# M3351 register map
File version: 1.0
Registers are 32-bit, read-write, reset 0x0 unless marked. A register's access mark holds for its fields unless they carry their own. Offsets are from the block's base; [hi:lo] are bit positions; {n}, {i} and the like mark numbered series; 'fields as' and 'values as' point back to an identical list.

## SYS — SYS Register Map
Base 0x40000000
0x00 SYS_PDID ro reset 0x3302140 — Part Device Identification Number Register
  [31:0] PDID — Part Device Identification Number (Read Only). This register reflects device part number code. Software can read this register to identify which device is used.
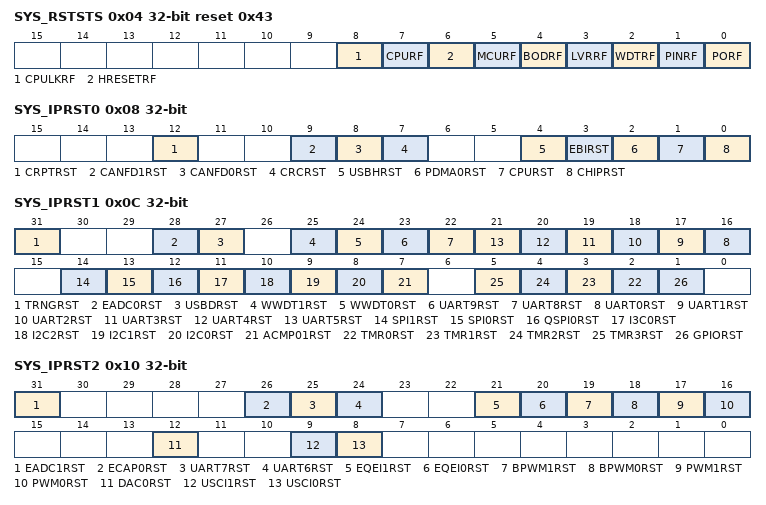
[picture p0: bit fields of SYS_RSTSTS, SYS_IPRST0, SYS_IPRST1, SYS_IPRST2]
0x04 SYS_RSTSTS reset 0x43 — System Reset Status Register
  [8] CPULKRF — CPU Lockup Reset Flag. Note 1: Write 1 to clear this bit to 0. Note 2: When CPU lockup happened under ICE is connected, this flag will set to 1 but chip will not reset.
    0=No reset from CPU lockup happened; 1=The Cortex-M33 lockup happened and chip is reset
  [7] CPURF — CPU Reset Flag. The CPU reset flag is set by hardware if software writes CPURST (SYS_IPRST0[1]) 1 to reset Cortex-M33 Core and Flash Memory Controller (FMC). Note: Write 1 to clear this bit to 0.
    0=No reset from CPU; 1=The Cortex-M33 Core and FMC are reset by software setting CPURST to 1
  [6] HRESETRF — HRESET Reset Flag. The HRESET reset flag is set by the 'Reset Signal' from the HRESET. Note 1: Write 1 to clear this bit to 0. Note 2: HRESET includes: POR, Reset Pin, LVR, BOD, WDT, WWDT, CPU lockup, CHIP and MCU reset.
    0=No reset from HRESET; 1=Reset from HRESET
  [5] MCURF — MCU Reset Flag. The MCU reset flag is set by the 'Reset Signal' from the Cortex-M33 Core to indicate the previous reset source. Note: Write 1 to clear this bit to 0.
    0=No reset from Cortex-M33; 1=The Cortex-M33 had issued the reset signal to reset the system by writing 1 to the bit SYSRESETREQ(AIRCR[2], Application Interrupt and Reset Control Register, address = 0xE000ED0C) in system control registers of Cortex-M33 core
  [4] BODRF — BOD Reset Flag. The BOD reset flag is set by the 'Reset Signal' from the Brown-Out Detector to indicate the previous reset source. Note: Write 1 to clear this bit to 0.
    0=No reset from BOD; 1=The BOD had issued the reset signal to reset the system
  [3] LVRRF — LVR Reset Flag. The LVR reset flag is set by the 'Reset Signal' from the Low Voltage Reset Controller to indicate the previous reset source. Note: Write 1 to clear this bit to 0.
    0=No reset from LVR; 1=LVR controller had issued the reset signal to reset the system
  [2] WDTRF — WDT Reset Flag. The WDT reset flag is set by the 'Reset Signal' from the Watchdog Timer or Window Watchdog Timer to indicate the previous reset source. Note 1: Write 1 to clear this bit to 0. Note 2: Watchdog Timer register RSTF(WDT_CTL[2]) bit is set if the system has been reset by WDT time-out reset. Window Watchdog Timer register WWDTRF(WWDT_STATUS[1]) bit is set if the system has been reset by WWDT time-out reset.
    0=No reset from watchdog timer or window watchdog timer; 1=The watchdog timer or window watchdog timer had issued the reset signal to reset the system
  [1] PINRF — NRESET Pin Reset Flag. The nRESET pin reset flag is set by the 'Reset Signal' from the nRESET pin to indicate the previous reset source. Note: Write 1 to clear this bit to 0.
    0=No reset from nRESET pin; 1=Pin nRESET had issued the reset signal to reset the system
  [0] PORF — POR Reset Flag. The POR reset flag is set by the 'Reset Signal' from the Power-on Reset (POR) Controller or bit CHIPRST (SYS_IPRST0[0]) to indicate the previous reset source. Note: Write 1 to clear this bit to 0.
    0=No reset from POR or CHIPRST; 1=Power-on Reset (POR) or CHIPRST had issued the reset signal to reset the system
0x08 SYS_IPRST0 — Peripheral Reset Control Register 0
  [12] CRPTRST — CRYPTO Controller Reset (Write Protect). Setting this bit to 1 will generate a reset signal to the CRYPTO controller. User needs to set this bit to 0 to release from the reset state. Note: This bit is write protected. Refer to the SYS_REGLCTL register.
    0=CRYPTO controller normal operation; 1=CRYPTO controller reset
  [9] CANFD1RST — CANFD1 Controller Reset (Write Protect). Setting this bit to 1 will generate a reset signal to the CANFD1 controller. User needs to set this bit to 0 to release from reset state. Note: This bit is write protected. Refer to the SYS_REGLCTL register.
    0=CANFD1 controller normal operation; 1=CANFD1 controller reset
  [8] CANFD0RST — CANFD0 Controller Reset (Write Protect). Setting this bit to 1 will generate a reset signal to the CANFD0 controller. User needs to set this bit to 0 to release from reset state. Note: This bit is write protected. Refer to the SYS_REGLCTL register.
    0=CANFD0 controller normal operation; 1=CANFD0 controller reset
  [7] CRCRST — CRC Calculation Controller Reset (Write Protect). Set this bit to 1 will generate a reset signal to the CRC calculation controller. User needs to set this bit to 0 to release from the reset state. Note: This bit is write protected. Refer to the SYS_REGLCTL register.
    0=CRC calculation controller normal operation; 1=CRC calculation controller reset
  [4] USBHRST — USBH Controller Reset (Write Protect). Setting this bit to 1 will generate a reset signal to the USBH controller. User needs to set this bit to 0 to release from the reset state. Note: This bit is write protected. Refer to the SYS_REGLCTL register.
    0=USBH controller normal operation; 1=USBH controller reset
  [3] EBIRST — EBI Controller Reset (Write Protect). Set this bit to 1 will generate a reset signal to the EBI controller. User needs to set this bit to 0 to release from the reset state. Note: This bit is write protected. Refer to the SYS_REGLCTL register.
    0=EBI controller normal operation; 1=EBI controller reset
  [2] PDMA0RST — PDMA0 Controller Reset (Write Protect). Setting this bit to 1 will generate a reset signal to the PDMA0 controller. User needs to set this bit to 0 to release from reset state. Note: This bit is write protected. Refer to the SYS_REGLCTL register.
    0=PDMA0 controller normal operation; 1=PDMA0 controller reset
  [1] CPURST — Processor Core One-shot Reset (Write Protect). Setting this bit will only reset the processor core and Flash Memory Controller(FMC), and this bit will automatically return to 0 after the 2 clock cycles. Note: This bit is write protected. Refer to the SYS_REGLCTL register.
    0=Processor core normal operation; 1=Processor core one-shot reset
  [0] CHIPRST — Chip One-shot Reset (Write Protect). Setting this bit will reset the whole chip, including Processor core and all peripherals, and this bit will automatically return to 0 after the 2 clock cycles. The CHIPRST is same as the POR reset, all the chip controllers are reset and the chip setting from Flash are also reload. About the difference between CHIPRST and SYSRESETREQ(AIRCR[2]), please refer to System Reset section. Note: This bit is write protected. Refer to the SYS_REGLCTL register.
    0=Chip normal operation; 1=Chip one-shot reset
0x0C SYS_IPRST1 — Peripheral Reset Control Register 1
  [31] TRNGRST — TRNG Controller Reset. Setting this bit to 1 will generate a reset signal to the TRNG controller. User needs to set this bit to 0 to release from reset state.
    0=TRNG controller normal operation; 1=TRNG controller reset
  [28] EADC0RST — EADC0 Controller Reset. Setting this bit to 1 will generate a reset signal to the EADC0 controller. User needs to set this bit to 0 to release from reset state.
    0=EADC0 controller normal operation; 1=EADC0 controller reset
  [27] USBDRST — USBD Controller Reset. Setting this bit to 1 will generate a reset signal to the USBD controller. User needs to set this bit to 0 to release from reset state.
    0=USBD controller normal operation; 1=USBD controller reset
  [25] WWDT1RST — WWDT1 Controller Reset. Setting this bit to 1 will generate a reset signal to the WWDT1 controller. User needs to set this bit to 0 to release from reset state.
    0=WWDT1 controller normal operation; 1=WWDT1 controller reset
  [24] WWDT0RST — WWDT0 Controller Reset. Setting this bit to 1 will generate a reset signal to the WWDT0 controller. User needs to set this bit to 0 to release from reset state.
    0=WWDT0 controller normal operation; 1=WWDT0 controller reset
  [23] UART9RST — UART9 Controller Reset. Setting this bit to 1 will generate a reset signal to the UART9 controller. User needs to set this bit to 0 to release from reset state.
    0=UART9 controller normal operation; 1=UART9 controller reset
  [22] UART8RST — UART8 Controller Reset. Setting this bit to 1 will generate a reset signal to the UART8 controller. User needs to set this bit to 0 to release from reset state.
    0=UART8 controller normal operation; 1=UART8 controller reset
  [n+16] UART{n}RST (n=0..5) — UART{n} Controller Reset. Setting this bit to 1 will generate a reset signal to the UART{n} controller. User needs to set this bit to 0 to release from reset state.
    0=UART{n} controller normal operation; 1=UART{n} controller reset
  [14] SPI1RST — SPI1 Controller Reset. Setting this bit to 1 will generate a reset signal to the SPI1 controller. User needs to set this bit to 0 to release from reset state.
    0=SPI1 controller normal operation; 1=SPI1 controller reset
  [13] SPI0RST — SPI0 Controller Reset. Setting this bit to 1 will generate a reset signal to the SPI0 controller. User needs to set this bit to 0 to release from reset state.
    0=SPI0 controller normal operation; 1=SPI0 controller reset
  [12] QSPI0RST — QSPI0 Controller Reset. Setting this bit to 1 will generate a reset signal to the QSPI0 controller. User needs to set this bit to 0 to release from reset state.
    0=QSPI0 controller normal operation; 1=QSPI0 controller reset
  [11] I3C0RST — I3C0 Controller Reset. Setting this bit to 1 will generate a reset signal to the I3C0 controller. User needs to set this bit to 0 to release from reset state.
    0=I3C0 normal operation; 1=I3C0 reset
  [10] I2C2RST — I2C2 Controller Reset. Setting this bit to 1 will generate a reset signal to the I2C2 controller. User needs to set this bit to 0 to release from reset state.
    0=I2C2 controller normal operation; 1=I2C2 controller reset
  [9] I2C1RST — I2C1 Controller Reset. Setting this bit to 1 will generate a reset signal to the I2C1 controller. User needs to set this bit to 0 to release from reset state.
    0=I2C1 controller normal operation; 1=I2C1 controller reset
  [8] I2C0RST — I2C0 Controller Reset. Setting this bit to 1 will generate a reset signal to the I2C0 controller. User needs to set this bit to 0 to release from reset state.
    0=I2C0 controller normal operation; 1=I2C0 controller reset
  [7] ACMP01RST — Analog Comparator 0/1 Controller Reset. Setting this bit to 1 will generate a reset signal to the ACMP01 controller. User needs to set this bit to 0 to release from reset state.
    0=Analog Comparator 0/1 controller normal operation; 1=Analog Comparator 0/1 controller reset
  [n+2] TMR{n}RST (n=0..3) — Timer{n} Controller Reset. Setting this bit to 1 will generate a reset signal to the Timer{n} controller. User needs to set this bit to 0 to release from reset state.
    0=Timer{n} controller normal operation; 1=Timer{n} controller reset
  [1] GPIORST — GPIO Controller Reset. Setting this bit to 1 will generate a reset signal to the GPIO controller. User needs to set this bit to 0 to release from reset state.
    0=GPIO controller normal operation; 1=GPIO controller reset
0x10 SYS_IPRST2 — Peripheral Reset Control Register 2
  [31] EADC1RST — EADC1 Controller Reset. Setting this bit to 1 will generate a reset signal to the EADC1 controller. User needs to set this bit to 0 to release from reset state.
    0=EADC1 controller normal operation; 1=EADC1 controller reset
  [26] ECAP0RST — ECAP0 Controller Reset. Setting this bit to 1 will generate a reset signal to the ECAP0 controller. User needs to set this bit to 0 to release from reset state.
    0=ECAP0 controller normal operation; 1=ECAP0 controller reset
  [25] UART7RST — UART7 Controller Reset. Setting this bit to 1 will generate a reset signal to the UART7 controller. User needs to set this bit to 0 to release from reset state.
    0=UART7 controller normal operation; 1=UART7 controller reset
  [24] UART6RST — UART6 Controller Reset. Setting this bit to 1 will generate a reset signal to the UART6 controller. User needs to set this bit to 0 to release from reset state.
    0=UART6 controller normal operation; 1=UART6 controller reset
  [21] EQEI1RST — EQEI1 Controller Reset. Setting this bit to 1 will generate a reset signal to the EQEI1 controller. User needs to set this bit to 0 to release from reset state.
    0=EQEI1 controller normal operation; 1=EQEI1 controller reset
  [20] EQEI0RST — EQEI0 Controller Reset. Setting this bit to 1 will generate a reset signal to the EQEI0 controller. User needs to set this bit to 0 to release from reset state.
    0=EQEI0 controller normal operation; 1=EQEI0 controller reset
  [19] BPWM1RST — BPWM1 Controller Reset. Setting this bit to 1 will generate a reset signal to the BPWM1 controller. User needs to set this bit to 0 to release from reset state.
    0=BPWM1 controller normal operation; 1=BPWM1 controller reset
  [18] BPWM0RST — BPWM0 Controller Reset. Setting this bit to 1 will generate a reset signal to the BPWM0 controller. User needs to set this bit to 0 to release from reset state.
    0=BPWM0 controller normal operation; 1=BPWM0 controller reset
  [17] PWM1RST — PWM1 Controller Reset. Setting this bit to 1 will generate a reset signal to the PWM1 controller. User needs to set this bit to 0 to release from reset state.
    0=PWM1 controller normal operation; 1=PWM1 controller reset
  [16] PWM0RST — PWM0 Controller Reset. Setting this bit to 1 will generate a reset signal to the PWM0 controller. User needs to set this bit to 0 to release from reset state.
    0=PWM0 controller normal operation; 1=PWM0 controller reset
  [12] DAC0RST — DAC0 Controller Reset. Setting this bit to 1 will generate a reset signal to the DAC0 controller. User needs to set this bit to 0 to release from reset state.
    0=DAC0 controller normal operation; 1=DAC0 controller reset
  [9] USCI1RST — USCI1 Controller Reset. Setting this bit to 1 will generate a reset signal to the USCI1 controller. User needs to set this bit to 0 to release from reset state.
    0=USCI1 controller normal operation; 1=USCI1 controller reset
  [8] USCI0RST — USCI0 Controller Reset. Setting this bit to 1 will generate a reset signal to the USCI0 controller. User needs to set this bit to 0 to release from reset state.
    0=USCI0 controller normal operation; 1=USCI0 controller reset
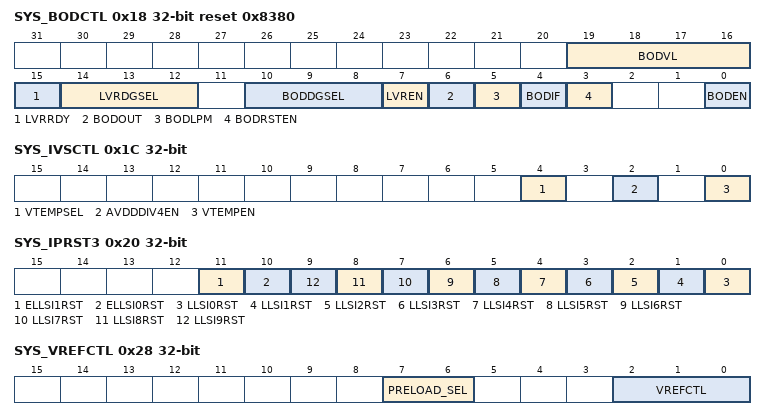
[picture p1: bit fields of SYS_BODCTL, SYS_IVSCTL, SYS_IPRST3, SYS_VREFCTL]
0x18 SYS_BODCTL reset 0x8380 (reset mask 0xFFF0FFF0) — Brown-out Detector Control Register
  [19:16] BODVL — Brown-out Detector Threshold Voltage Selection (Write Protect). The default value is set by Flash controller user configuration register CBOV ({1'b1, CONFIG0 [23:21]}). Note: These bits are write protected. Refer to the SYS_REGLCTL register.
    11=Brown-Out Detector threshold voltage is 2.8V; 13=Brown-Out Detector threshold voltage is 3.7V; 15=Brown-Out Detector threshold voltage is 4.4V
  [15] LVRRDY — Low Voltage Reset Ready Flag (Read Only). When the LVR function first enable, need more HCLK to wait LVR ready.
    0=Low Voltage Reset function not ready; 1=Low Voltage Reset function ready
  [14:12] LVRDGSEL — LVR Output De-glitch Time Select (Write Protect). Note: These bits are write protected. Refer to the SYS_REGLCTL register.
    0=Without de-glitch function; 1=4 system clock (HCLK); 2=8 system clock (HCLK); 3=16 system clock (HCLK); 4=32 system clock (HCLK); 5=64 system clock (HCLK); 6=128 system clock (HCLK); 7=256 system clock (HCLK)
  [10:8] BODDGSEL — Brown-out Detector Output De-glitch Time Select (Write Protect). Note: These bits are write protected. Refer to the SYS_REGLCTL register.
    0=BOD output is sampled by LIRC clock; 1=4 system clock (HCLK); 2=8 system clock (HCLK); 3=16 system clock (HCLK); 4=32 system clock (HCLK); 5=64 system clock (HCLK); 6=128 system clock (HCLK); 7=256 system clock (HCLK)
  [7] LVREN — Low Voltage Reset Enable Bit (Write Protect). The LVR function resets the chip when the input power voltage is lower than LVR circuit setting. Note 1: After enabling the bit, the LVR function will be active with 100us ~ 200us delay for LVR output stable. LVRRDY(SYS_BODCTL[15]) is used to indicate LVR ready status. Note 2: This bit is write protected. Refer to the SYS_REGLCTL register.
    0=Low Voltage Reset function Disabled; 1=Low Voltage Reset function Enabled (default)
  [6] BODOUT — Brown-out Detector Output Status. It means the detected voltage is lower than BODVL setting. If the BODEN is 0, BOD function disabled, this bit always responds 0.
    0=Brown-out Detector output status is 0; 1=Brown-out Detector output status is 1
  [5] BODLPM — Brown-out Detector Low Power Mode (Write Protect). Note 1: The BOD consumes about 100uA in normal mode, the low power mode can reduce the current to about 1/10 but slow the BOD response. Note 2: This bit is write protected. Refer to the SYS_REGLCTL register.
    0=BOD operate in normal mode (default); 1=BOD Low Power mode Enabled
  [4] BODIF — Brown-out Detector Interrupt Flag. Note: Write 1 to clear this bit to 0.
    0=Brown-out Detector does not detect any voltage draft at AVDD down through or up through the voltage of BODVL setting; 1=When Brown-out Detector detects the AVDD is dropped down through the voltage of BODVL setting or the AVDD is raised up through the voltage of BODVL setting, this bit is set to 1 and the brown-out interrupt is requested if brown-out interrupt is enabled
  [3] BODRSTEN — Brown-out Reset Enable Bit (Write Protect). The default value is set by Flash controller user configuration register CBORST(CONFIG0[20]) bit. Note 1: While the Brown-out Detector function is enabled (BODEN high) and BOD reset function is enabled (BODRSTEN high), BOD will assert a signal to reset chip when the detected voltage is lower than the threshold (BODOUT high). While the BOD function is enabled (BODEN high) and BOD interrupt function is enabled (BODRSTEN low), BOD will assert an interrupt if BODIF is high. BOD interrupt will keep till the BODIF set to 0. BOD interrupt can be blocked by disabling the NVIC BOD interrupt or disabling BOD function (set BODEN low). Note 2: This bit is write protected. Refer to the SYS_REGLCTL register.
    0=Brown-out 'INTERRUPT' function Enabled; 1=Brown-out 'RESET' function Enabled
  [0] BODEN — Brown-out Detector Enable Bit (Write Protect). The default value is set by Flash controller user configuration register CBODEN (CONFIG0 [19]). Note: This bit is write protected. Refer to the SYS_REGLCTL register.
    0=Brown-out Detector function Disabled; 1=Brown-out Detector function Enabled
0x1C SYS_IVSCTL — Internal Voltage Source Control Register
  [4] VTEMPSEL — Temperature Sensor Slope Select Bit. This bit is used to select temperature sensor slope trend.
    0=Temperature sensor CTAT slope; 1=Temperature sensor PTAT slope
  [2] AVDDDIV4EN — AVDD Divide 4 Enable Bit. This bit is used to enable/disable AVDD divide 4 function. Note: After this bit is set to 1, the value of AVDD divide 4 output voltage can be obtained from ADC conversion result.
    0=AVDD divide 4 function Disabled (default); 1=AVDD divide 4 function Enabled
  [0] VTEMPEN — Temperature Sensor Enable Bit. This bit is used to enable/disable temperature sensor function.
    0=Temperature sensor function Disabled (default); 1=Temperature sensor function Enabled
0x20 SYS_IPRST3 — Peripheral Reset Control Register 3
  [11] ELLSI1RST — ELLSI1 Controller Reset
    0=ELLSI1 normal operation; 1=ELLSI1 reset
  [10] ELLSI0RST — ELLSI0 Controller Reset
    0=ELLSI0 normal operation; 1=ELLSI0 reset
  [n] LLSI{n}RST (n=0..9) — LLSI{n} Controller Reset
    0=LLSI{n} normal operation; 1=LLSI{n} reset
0x28 SYS_VREFCTL — VREF Control Register
  [7:6] PRELOAD_SEL — VREF Preload Time Select (Write Protect). Note: These bits are write protected. Refer to the SYS_REGLCTL register.
    0=60us (default); 1=966us; 2=2000us; 3=2.65ms
  [2:0] VREFCTL — VREF Control Bits (Write Protect). Note: These bits are write protected. Refer to the SYS_REGLCTL register.
    0=VREF is from external pin; 3=VREF is internal 2.56V; 5=VREF is internal 3.072V; 7=VREF is internal 4.096V
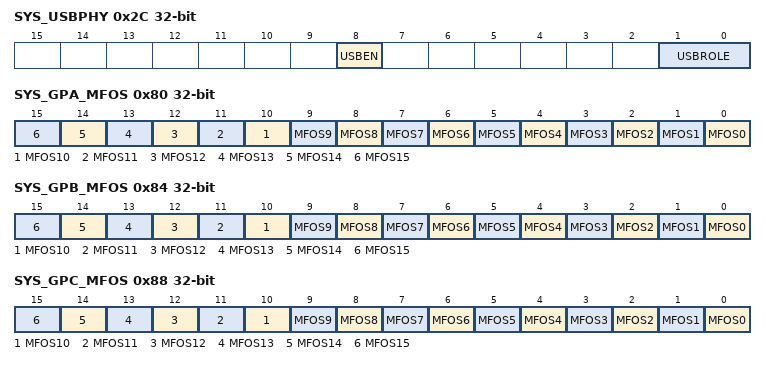
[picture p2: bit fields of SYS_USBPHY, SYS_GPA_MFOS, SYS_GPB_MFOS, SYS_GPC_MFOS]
0x2C SYS_USBPHY — USB PHY Control Register
  [8] USBEN — USB PHY Enable. This bit is used to enable/disable USB PHY.
    0=USB PHY Disabled; 1=USB PHY Enabled
  [1:0] USBROLE — USB Role Option (Write Protect). These two bits are used to select the role of USB. Note: These bits are write protected. Refer to the SYS_REGLCTL register.
    0=Standard USB Device mode; 1=Standard USB Host mode
0x80 SYS_GPA_MFOS — GPIOA Multiple Function Output Select Register
  [all] fields
    0=Multiple function pin output mode type is Push-pull mode; 1=Multiple function pin output mode type is Open-drain mode
  [n] MFOS{n} (n=0..15) — GPIOA-H Pin[n] Multiple Function Pin Output Mode Select. This bit used to select multiple function pin output mode type for Px.n pin.
0x84 SYS_GPB_MFOS — GPIOB Multiple Function Output Select Register
  fields as SYS_GPA_MFOS
0x88 SYS_GPC_MFOS — GPIOC Multiple Function Output Select Register
  fields as SYS_GPA_MFOS
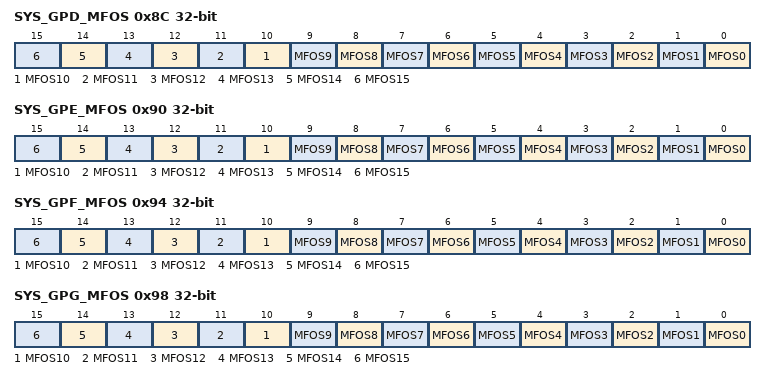
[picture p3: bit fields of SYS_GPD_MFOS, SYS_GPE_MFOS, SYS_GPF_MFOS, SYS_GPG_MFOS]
0x8C SYS_GPD_MFOS — GPIOD Multiple Function Output Select Register
  fields as SYS_GPA_MFOS
0x90 SYS_GPE_MFOS — GPIOE Multiple Function Output Select Register
  fields as SYS_GPA_MFOS
0x94 SYS_GPF_MFOS — GPIOF Multiple Function Output Select Register
  fields as SYS_GPA_MFOS
0x98 SYS_GPG_MFOS — GPIOG Multiple Function Output Select Register
  fields as SYS_GPA_MFOS
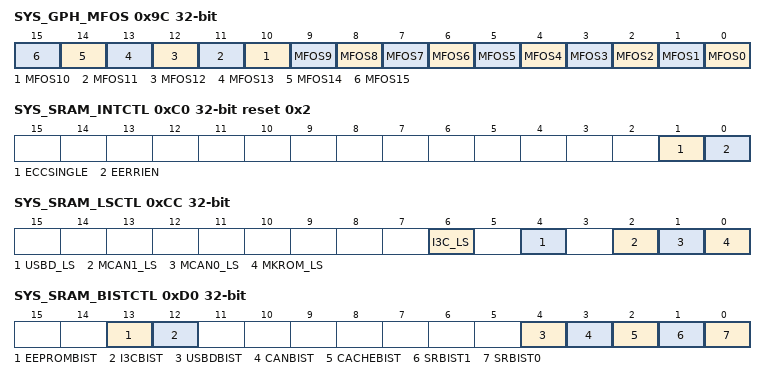
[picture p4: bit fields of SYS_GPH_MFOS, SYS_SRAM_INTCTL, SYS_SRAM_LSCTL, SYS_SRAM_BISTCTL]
0x9C SYS_GPH_MFOS — GPIOH Multiple Function Output Select Register
  fields as SYS_GPA_MFOS
0xA8 SYS_VTORSET — VTOR Setting Register
  [31:7] VTORSET — VTOR Setting After SPD Wakeup (Write Protect). This is the register to set the address of vector table after chip is waked up from SPD mode. The value will be loaded to Vector Table Offset Register, which is at the address 0xE000ED08, when chip wake up from SPD mode. Note: These bits are write protected. Refer to the SYS_REGLCTL register.
0xC0 SYS_SRAM_INTCTL reset 0x2 — System SRAM Secure ECC Interrupt Enable Control Register
  [1] ECCSINGLE — SRAM ECC Check single Error Enable Bit
    0=SRAM ECC check single error Disabled; 1=SRAM ECC check single error Enabled
  [0] EERRIEN — SRAM ECC Check Error Interrupt Enable Bit
    0=SRAM ECC check error interrupt Disabled; 1=SRAM ECC check error interrupt Enabled
0xC4 SYS_SRAM_STATUS — System SRAM Secure ECC Status Register
  [0] EERRIF — SRAM ECC Check Error Flag. This bit indicates the System SRAM ECC error occurred. Write 1 to clear this to 0. *This function only works if ECCEN set to 1.
    0=No System SRAM ECC error; 1=System SRAM ECC error occur
0xC8 SYS_SRAM_ERRADDR ro — System SRAM Secure ECC Error Address Register
  [31:0] ERRADDR — System SRAM ECC Error Address (Read Only). This register shows system SRAM ECC error byte address.(If ECC errors are detected in multiple SRAM banks, a single address will be randomly chosen for reporting). Note: This function only works if ECCEN set to 1.
0xCC SYS_SRAM_LSCTL — SRAM Light Sleep Control Register
  [all] fields
    0=Light Sleep disable; 1=Light Sleep enable, SRAM goes into low leakage mode, there is no change in the output state
  [6] I3C_LS — I3C SRAM Light Sleep Mode Enable bit (Write Protect). Note: This bit is write protected. Refer to the SYS_REGLCTL register.
  [4] USBD_LS — USBD SRAM Light Sleep Mode Enable bit (Write Protect). Note: This bit is write protected. Refer to the SYS_REGLCTL register.
  [2] MCAN1_LS — MCAN1 SRAM Light Sleep Mode Enable bit (Write Protect). Note: This bit is write protected. Refer to the SYS_REGLCTL register.
  [1] MCAN0_LS — MCAN0 SRAM Light Sleep Mode Enable bit (Write Protect). Note: This bit is write protected. Refer to the SYS_REGLCTL register.
  [0] MKROM_LS — MKROM Light Sleep Mode Enable bit (Write Protect). Note: This bit is write protected. Refer to the SYS_REGLCTL register.
0xD0 SYS_SRAM_BISTCTL — System SRAM BIST Test Control Register
  [13] EEPROMBIST — EEPROM SRAM BIST Enable Bit (Write Protect). This bit enables BIST test for EEPROM SRAM. Note: This bit is write protected. Refer to the SYS_REGLCTL register.
    0=EEPROM SRAM BIST Disabled; 1=EEPROM SRAM BIST Enabled
  [12] I3CBIST — I3C SRAM BIST Enable Bit (Write Protect). This bit enables BIST test for I3C SRAM. Note: This bit is write protected. Refer to the SYS_REGLCTL register.
    0=I3C SRAM BIST Disabled; 1=I3C SRAM BIST Enabled
  [4] USBDBIST — USBD SRAM BIST Enable Bit (Write Protect). This bit enables BIST test for USBD SRAM. Note: This bit is write protected. Refer to the SYS_REGLCTL register.
    0=USBD SRAM BIST Disabled; 1=USBD SRAM BIST Enabled
  [3] CANBIST — CAN SRAM BIST Enable Bit (Write Protect). This bit enables BIST test for CAN SRAM. Note: This bit is write protected. Refer to the SYS_REGLCTL register.
    0=CAN SRAM BIST Disabled; 1=CAN SRAM BIST Enabled
  [2] CACHEBIST — CACHE SRAM BIST Enable Bit (Write Protect). This bit enables BIST test for CACHE SRAM. Note: This bit is write protected. Refer to the SYS_REGLCTL register.
    0=CACHE SRAM BIST Disabled; 1=CACHE SRAM BIST Enabled
  [1] SRBIST1 — System SRAM Bank1 BIST Enable Bit (Write Protect). This bit enables BIST test for system SRAM bank1. Note: This bit is write protected. Refer to the SYS_REGLCTL register.
    0=System SRAM bank1 BIST Disabled; 1=System SRAM bank1 BIST Enabled
  [0] SRBIST0 — System SRAM Bank0 BIST Enable Bit (Write Protect). This bit enables BIST test for system SRAM bank0. Note: This bit is write protected. Refer to the SYS_REGLCTL register.
    0=System SRAM bank0 BIST Disabled; 1=System SRAM bank0 BIST Enabled
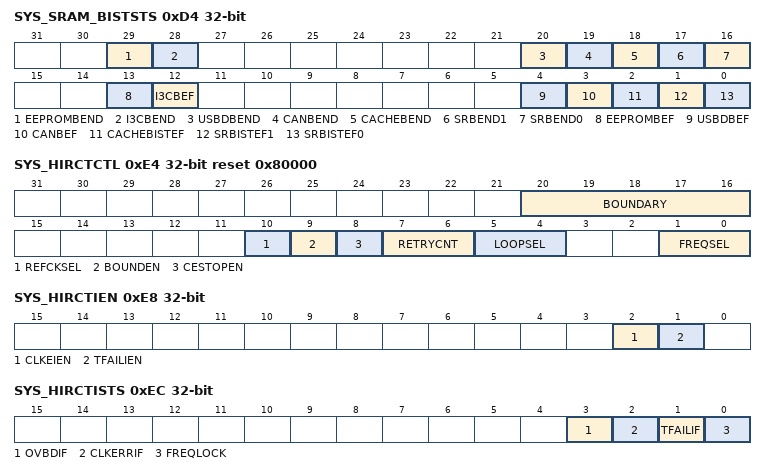
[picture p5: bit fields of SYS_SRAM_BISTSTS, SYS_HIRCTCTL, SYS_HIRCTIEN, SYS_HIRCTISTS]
0xD4 SYS_SRAM_BISTSTS ro (reset mask 0xF000F00) — System SRAM BIST Test Status Register
  [29] EEPROMBEND — EEPROM SRAM BIST Test Finish (Read Only)
    0=EEPROM SRAM BIST is active; 1=EEPROM SRAM BIST test finished
  [28] I3CBEND — I3C SRAM BIST Test Finish (Read Only)
    0=I3C SRAM BIST is active; 1=I3C SRAM BIST test finished
  [20] USBDBEND — USBD SRAM BIST Test Finish (Read Only)
    0=USBD SRAM BIST is active; 1=USBD SRAM BIST test finished
  [19] CANBEND — CAN SRAM BIST Test Finish (Read Only). Note: All of the CAN SRAM macros BIST finished; this flag is 1.
    0=CAN SRAM BIST is active; 1=CAN SRAM BIST test finished
  [18] CACHEBEND — CACHE SRAM BIST Test Finish (Read Only)
    0=CACHE SRAM BIST is active; 1=CACHE SRAM BIST test finished
  [17] SRBEND1 — System SRAM Bnak1 BIST Test Finish (Read Only)
    0=System SRAM bank1 BIST is active; 1=System SRAM bank1 BIST finished
  [16] SRBEND0 — System SRAM Bank0 BIST Test Finish (Read Only)
    0=System SRAM bank0 BIST active; 1=System SRAM bank0 BIST finished
  [13] EEPROMBEF — EEPROM SRAM BIST Fail Flag (Read Only)
    0=EEPROM SRAM BIST test pass; 1=EEPROM SRAM BIST test fail
  [12] I3CBEF — I3C SRAM BIST Fail Flag (Read Only)
    0=I3C SRAM BIST test pass; 1=I3C SRAM BIST test fail
  [4] USBDBEF — USBD SRAM BIST Fail Flag (Read Only)
    0=USBD SRAM BIST test pass; 1=USBD SRAM BIST test fail
  [3] CANBEF — CAN SRAM BIST Fail Flag (Read Only). Note: Any of the CAN SRAM macros BIST fail, this flag is 1.
    0=CAN SRAM BIST test pass; 1=CAN SRAM BIST test fail
  [2] CACHEBISTEF — CACHE SRAM BIST Fail Flag (Read Only)
    0=CACHE RAM BIST test pass; 1=CACHE RAM BIST test fail
  [1] SRBISTEF1 — System SRAM Bank1 BIST Fail Flag (Read Only)
    0=System SRAM bank1 BIST test pass; 1=System SRAM bank1 BIST test fail
  [0] SRBISTEF0 — System SRAM Bank0 BIST Fail Flag (Read Only)
    0=System SRAM bank0 BIST test pass; 1=System SRAM bank0 BIST test fail
0xDC SYS_SRAM_ECCEN (reset mask 0xFFFFFFF0) — System SRAM ECC Control Register
  [0] ECCEN — SRAM ECC Function Enable. Note: When chip reset, default value comes from CONFIG0[29]
    0=No System SRAM ECC function; 1=System SRAM ECC error function
0xE4 SYS_HIRCTCTL reset 0x80000 — HIRC48M Trim Control Register
  [20:16] BOUNDARY — Boundary Selection. Fill the boundary range from 0x1 to 0x31, 0x0 is reserved. Note: This field is effective only when the BOUNDEN(SYS_HIRCTCTL[9]) is enabled.
  [10] REFCKSEL — Reference Clock Selection
    0=HIRC trim reference clock is from LXT (32.768 kHz); 1=HIRC trim reference clock is from internal USB synchronous mode
  [9] BOUNDEN — Boundary Enable Bit
    0=Boundary function Disabled; 1=Boundary function Enabled
  [8] CESTOPEN — Clock Error Stop Enable Bit
    0=The trim operation is keep going if clock is inaccuracy; 1=The trim operation is stopped if clock is inaccuracy
  [7:6] RETRYCNT — Trim Value Update Limitation Count. This field defines that how many times the auto trim circuit will try to update the HIRC trim value before the frequency of HIRC locked. Once the HIRC locked, the internal trim value update counter will be reset. If the trim value update counter reached this limitation value and frequency of HIRC still doesn't lock, the auto trim operation will be disabled and FREQSEL will be cleared to 00.
    0=Trim retry count limitation is 64 loops; 1=Trim retry count limitation is 128 loops; 2=Trim retry count limitation is 256 loops; 3=Trim retry count limitation is 512 loops
  [5:4] LOOPSEL — Trim Calculation Loop Selection. This field defines that trim value calculation is based on how many reference clocks. Note: For example, if LOOPSEL is set as 00, auto trim circuit will calculate trim value based on the average frequency difference in 4 clocks of reference clock.
    0=Trim value calculation is based on average difference in 4 clocks of reference clock; 1=Trim value calculation is based on average difference in 8 clocks of reference clock; 2=Trim value calculation is based on average difference in 16 clocks of reference clock; 3=Trim value calculation is based on average difference in 32 clocks of reference clock
  [1:0] FREQSEL — Trim Frequency Selection. This field indicates the target frequency of 48 MHz internal high speed RC oscillator (HIRC48M) auto trim. During auto trim operation, if clock error detected with CESTOPEN is set to 1 or trim retry limitation count reached, this field will be cleared to 00 automatically.
    0=Disable HIRC auto trim function; 1=Enable HIRC auto trim function and trim HIRC to 48 MHz
0xE8 SYS_HIRCTIEN — HIRC48M Trim Interrupt Enable Register
  [2] CLKEIEN — Clock Error Interrupt Enable Bit. This bit controls if CPU would get an interrupt while clock is inaccuracy during auto trim operation. If this bit is set to1, and CLKERRIF(SYS_HIRCTISTS[2]) is set during auto trim operation, an interrupt will be triggered to notify the clock frequency is inaccuracy.
    0=Disable CLKERRIF(SYS_HIRCTISTS[2]) status to trigger an interrupt to CPU; 1=Enable CLKERRIF(SYS_HIRCTISTS[2]) status to trigger an interrupt to CPU
  [1] TFAILIEN — Trim Failure Interrupt Enable Bit. This bit controls if an interrupt will be triggered while HIRC trim value update limitation count reached and HIRC frequency still not locked on target frequency set by FREQSEL(SYS_HIRCTCTL[1:0]). If this bit is high and TFAILIF(SYS_HIRCTISTS[1]) is set during auto trim operation, an interrupt will be triggered to notify that HIRC trim value update limitation count was reached.
    0=Disable TFAILIF(SYS_HIRCTISTS[1]) status to trigger an interrupt to CPU; 1=Enable TFAILIF(SYS_HIRCTISTS[1]) status to trigger an interrupt to CPU
0xEC SYS_HIRCTISTS — HIRC48M Trim Interrupt Status Register
  [3] OVBDIF — Over Boundary Status. When the over boundary function is set, if there occurs the over boundary condition, this flag will be set. Note: Write 1 to clear this flag.
    0=Over boundary condition did not occur; 1=Over boundary condition occurred
  [2] CLKERRIF — Clock Error Interrupt Status. When the frequency of 32.768 kHz external low speed crystal oscillator (LXT) or 48 MHz internal high speed RC oscillator (HIRC48M) is shift larger to unreasonable value, this bit will be set and to be an indicate that clock frequency is inaccuracy. Once this bit is set to 1, the auto trim operation stopped and FREQSEL(SYS_HIRCTCTL[1:0]) will be cleared to 00 by hardware automatically if CESTOPEN(SYS_HIRCTCTL[8]) is set to 1. If this bit is set and CLKEIEN(SYS_HIRCTIEN[2]) is high, an interrupt will be triggered to notify the clock frequency is inaccuracy. Write 1 to clear this to 0.
    0=Clock frequency is accuracy; 1=Clock frequency is inaccuracy
  [1] TFAILIF — Trim Failure Interrupt Status. This bit indicates that HIRC trim value update limitation count reached and the HIRC clock frequency still doesn't be locked. Once this bit is set, the auto trim operation stopped and FREQSEL(SYS_HIRCTCTL[1:0]) will be cleared to 00 by hardware automatically. If this bit is set and TFAILIEN(SYS_HIRCTIEN[1]) is high, an interrupt will be triggered to notify that HIRC trim value update limitation count was reached. Write 1 to clear this to 0.
    0=Trim value update limitation count does not reach; 1=Trim value update limitation count reached and HIRC frequency still not locked
  [0] FREQLOCK — HIRC Frequency Lock Status. This bit indicates the HIRC frequency is locked. This is a status bit and doesn't trigger any interrupt. Write 1 to clear this to 0. This bit will be set automatically, if the frequency is lock and the RC_TRIM is enabled.
    0=The internal high-speed oscillator frequency doesn't lock at 48 MHz yet; 1=The internal high-speed oscillator frequency locked at 48 MHz
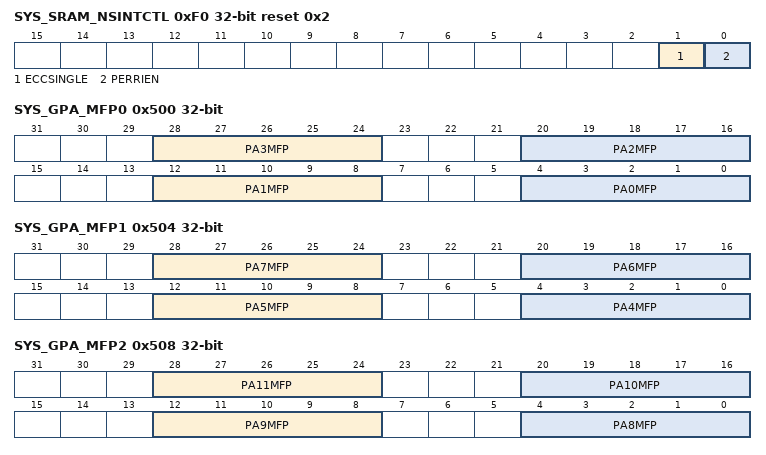
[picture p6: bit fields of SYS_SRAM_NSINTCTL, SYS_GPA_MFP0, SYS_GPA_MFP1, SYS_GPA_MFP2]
0xF0 SYS_SRAM_NSINTCTL reset 0x2 — System SRAM Non-Secure ECC Interrupt Enable Control Register
  [1] ECCSINGLE — SRAM ECC Single Error check
    0=The SRAM ECC logic non check single-bit error; 1=The SRAM ECC logic checks for single-bit error
  [0] PERRIEN — SRAM ECC Check Error Interrupt Enable Bit
    values as SYS_SRAM_INTCTL.EERRIEN
0xF4 SYS_SRAM_NSSTATUS — System SRAM Non-Secure ECC Status Register
  [0] PERRIF — SRAM Parity Check Error Flag. This bit indicates the System SRAM parity error occurred. Write 1 to clear this to 0. Note: This function only works if ECCEN set to 1.
    0=No System SRAM ECC error; 1=System SRAM ECC error occur
0xF8 SYS_SRAM_NSERRADDR ro — System SRAM Non-Secure ECC Error Address Register
  [31:0] ERRADDR — System SRAM ECC Error Address (Read Only). This register shows system SRAM ECC error byte address. *This function only works if ECCEN set to 1.
0x100 SYS_REGLCTL — Register Lock Control Register
  [7:0] REGLCTL — Register Lock Control Code (Write Only). Some registers have write-protection function. Writing these registers have to disable the protected function by writing the sequence value '59h', '16h', '88h' to this field. After this sequence is completed, the REGLCTL bit will be set to 1 and write-protection registers can be normal write. REGLCTL[0]. Register Lock Control Disable Index (Read Only)
    0=Write-protection Enabled for writing protected registers. Any write to the protected register is ignored; 1=Write-protection Disabled for writing protected registers
0x1EC SYS_PORDISAN — Analog POR Disable Control Register
  [15:0] POROFFAN — Power-on Reset Enable Bit (Write Protect). After powered on, User can turn off internal analog POR circuit to save power by writing 0x5AA5 to this field. The analog POR circuit will be active again when this field is set to another value or chip is reset by other reset source, including: nRESET, Watchdog, LVR reset, BOD reset, ICE reset command and the software-chip reset function. Note: These bits are write protected. Refer to the SYS_REGLCTL register.
0x400 SYS_AHBMCTL reset 0x1 — AHB Bus Matrix Priority Control Register
  [0] INTACTEN — Highest AHB Bus Priority of Cortex-M33 Core Enable Bit (Write Protect). Enable Cortex-M33 Core with Highest AHB Bus Priority in AHB Bus Matrix. Note: This bit is write protected. Refer to the SYS_REGLCTL register.
    0=Round-robin mode; 1=Cortex-M33 CPU with highest bus priority when interrupt occurred
0x500 SYS_GPA_MFP0 — GPIOA Multiple Function Control Register 0
  [28:24] PA3MFP — PA.3 Multi-function Pin Selection
  [20:16] PA2MFP — PA.2 Multi-function Pin Selection
  [12:8] PA1MFP — PA.1 Multi-function Pin Selection
  [4:0] PA0MFP — PA.0 Multi-function Pin Selection
0x504 SYS_GPA_MFP1 — GPIOA Multiple Function Control Register 1
  [28:24] PA7MFP — PA.7 Multi-function Pin Selection
  [20:16] PA6MFP — PA.6 Multi-function Pin Selection
  [12:8] PA5MFP — PA.5 Multi-function Pin Selection
  [4:0] PA4MFP — PA.4 Multi-function Pin Selection
0x508 SYS_GPA_MFP2 — GPIOA Multiple Function Control Register 2
  [28:24] PA11MFP — PA.11 Multi-function Pin Selection
  [20:16] PA10MFP — PA.10 Multi-function Pin Selection
  [12:8] PA9MFP — PA.9 Multi-function Pin Selection
  [4:0] PA8MFP — PA.8 Multi-function Pin Selection
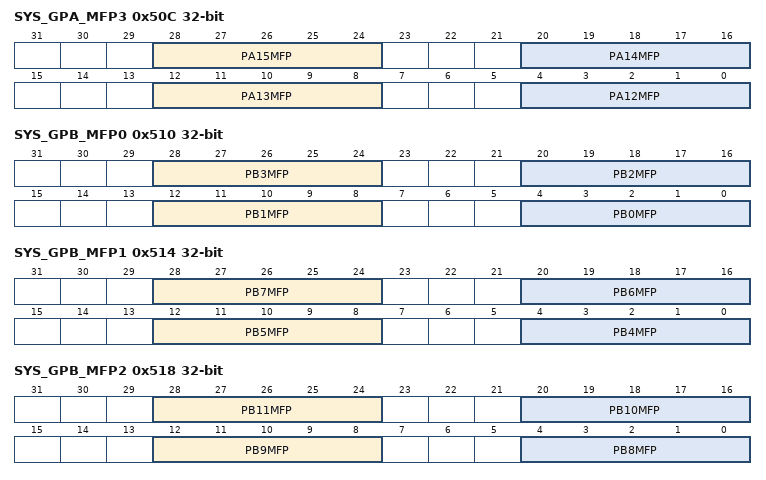
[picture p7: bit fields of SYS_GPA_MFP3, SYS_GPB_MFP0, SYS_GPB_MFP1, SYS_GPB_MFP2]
0x50C SYS_GPA_MFP3 — GPIOA Multiple Function Control Register 3
  [28:24] PA15MFP — PA.15 Multi-function Pin Selection
  [20:16] PA14MFP — PA.14 Multi-function Pin Selection
  [12:8] PA13MFP — PA.13 Multi-function Pin Selection
  [4:0] PA12MFP — PA.12 Multi-function Pin Selection
0x510 SYS_GPB_MFP0 — GPIOB Multiple Function Control Register 0
  [28:24] PB3MFP — PB.3 Multi-function Pin Selection
  [20:16] PB2MFP — PB.2 Multi-function Pin Selection
  [12:8] PB1MFP — PB.1 Multi-function Pin Selection
  [4:0] PB0MFP — PB.0 Multi-function Pin Selection
0x514 SYS_GPB_MFP1 — GPIOB Multiple Function Control Register 1
  [28:24] PB7MFP — PB.7 Multi-function Pin Selection
  [20:16] PB6MFP — PB.6 Multi-function Pin Selection
  [12:8] PB5MFP — PB.5 Multi-function Pin Selection
  [4:0] PB4MFP — PB.4 Multi-function Pin Selection
0x518 SYS_GPB_MFP2 — GPIOB Multiple Function Control Register 2
  [28:24] PB11MFP — PB.11 Multi-function Pin Selection
  [20:16] PB10MFP — PB.10 Multi-function Pin Selection
  [12:8] PB9MFP — PB.9 Multi-function Pin Selection
  [4:0] PB8MFP — PB.8 Multi-function Pin Selection
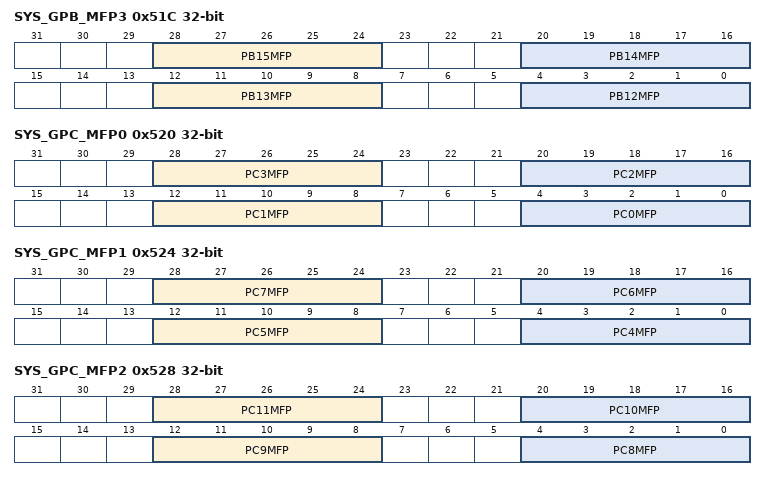
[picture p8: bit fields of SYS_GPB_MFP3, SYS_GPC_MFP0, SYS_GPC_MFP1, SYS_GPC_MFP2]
0x51C SYS_GPB_MFP3 — GPIOB Multiple Function Control Register 3
  [28:24] PB15MFP — PB.15 Multi-function Pin Selection
  [20:16] PB14MFP — PB.14 Multi-function Pin Selection
  [12:8] PB13MFP — PB.13 Multi-function Pin Selection
  [4:0] PB12MFP — PB.12 Multi-function Pin Selection
0x520 SYS_GPC_MFP0 — GPIOC Multiple Function Control Register 0
  [28:24] PC3MFP — PC.3 Multi-function Pin Selection
  [20:16] PC2MFP — PC.2 Multi-function Pin Selection
  [12:8] PC1MFP — PC.1 Multi-function Pin Selection
  [4:0] PC0MFP — PC.0 Multi-function Pin Selection
0x524 SYS_GPC_MFP1 — GPIOC Multiple Function Control Register 1
  [28:24] PC7MFP — PC.7 Multi-function Pin Selection
  [20:16] PC6MFP — PC.6 Multi-function Pin Selection
  [12:8] PC5MFP — PC.5 Multi-function Pin Selection
  [4:0] PC4MFP — PC.4 Multi-function Pin Selection
0x528 SYS_GPC_MFP2 — GPIOC Multiple Function Control Register 2
  [28:24] PC11MFP — PC.11 Multi-function Pin Selection
  [20:16] PC10MFP — PC.10 Multi-function Pin Selection
  [12:8] PC9MFP — PC.9 Multi-function Pin Selection
  [4:0] PC8MFP — PC.8 Multi-function Pin Selection
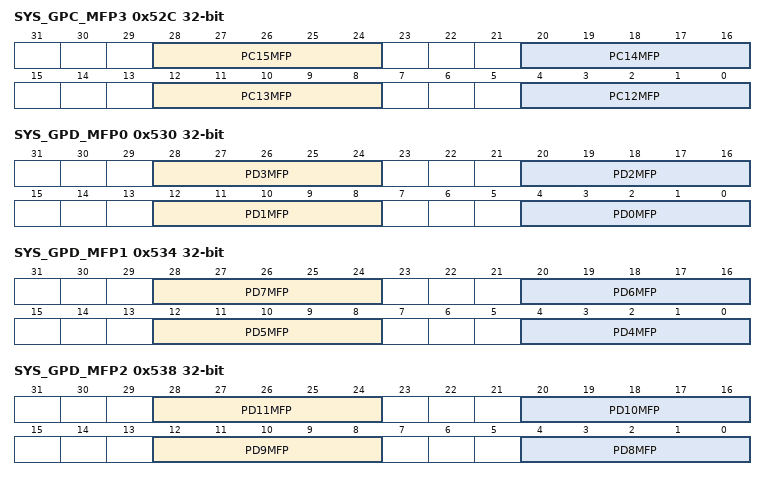
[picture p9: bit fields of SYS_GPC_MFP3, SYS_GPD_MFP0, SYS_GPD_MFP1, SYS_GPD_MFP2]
0x52C SYS_GPC_MFP3 — GPIOC Multiple Function Control Register 3
  [28:24] PC15MFP — PC.15 Multi-function Pin Selection
  [20:16] PC14MFP — PC.14 Multi-function Pin Selection
  [12:8] PC13MFP — PC.13 Multi-function Pin Selection
  [4:0] PC12MFP — PC.12 Multi-function Pin Selection
0x530 SYS_GPD_MFP0 — GPIOD Multiple Function Control Register 0
  [28:24] PD3MFP — PD.3 Multi-function Pin Selection
  [20:16] PD2MFP — PD.2 Multi-function Pin Selection
  [12:8] PD1MFP — PD.1 Multi-function Pin Selection
  [4:0] PD0MFP — PD.0 Multi-function Pin Selection
0x534 SYS_GPD_MFP1 — GPIOD Multiple Function Control Register 1
  [28:24] PD7MFP — PD.7 Multi-function Pin Selection
  [20:16] PD6MFP — PD.6 Multi-function Pin Selection
  [12:8] PD5MFP — PD.5 Multi-function Pin Selection
  [4:0] PD4MFP — PD.4 Multi-function Pin Selection
0x538 SYS_GPD_MFP2 — GPIOD Multiple Function Control Register 2
  [28:24] PD11MFP — PD.11 Multi-function Pin Selection
  [20:16] PD10MFP — PD.10 Multi-function Pin Selection
  [12:8] PD9MFP — PD.9 Multi-function Pin Selection
  [4:0] PD8MFP — PD.8 Multi-function Pin Selection
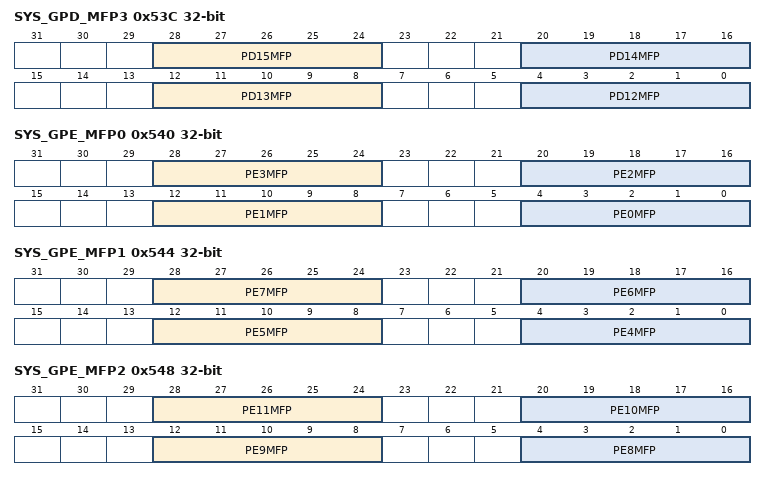
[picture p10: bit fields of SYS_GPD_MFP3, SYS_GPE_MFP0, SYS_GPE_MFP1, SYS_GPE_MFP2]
0x53C SYS_GPD_MFP3 — GPIOD Multiple Function Control Register 3
  [28:24] PD15MFP — PD.15 Multi-function Pin Selection
  [20:16] PD14MFP — PD.14 Multi-function Pin Selection
  [12:8] PD13MFP — PD.13 Multi-function Pin Selection
  [4:0] PD12MFP — PD.12 Multi-function Pin Selection
0x540 SYS_GPE_MFP0 — GPIOE Multiple Function Control Register 0
  [28:24] PE3MFP — PE.3 Multi-function Pin Selection
  [20:16] PE2MFP — PE.2 Multi-function Pin Selection
  [12:8] PE1MFP — PE.1 Multi-function Pin Selection
  [4:0] PE0MFP — PE.0 Multi-function Pin Selection
0x544 SYS_GPE_MFP1 — GPIOE Multiple Function Control Register 1
  [28:24] PE7MFP — PE.7 Multi-function Pin Selection
  [20:16] PE6MFP — PE.6 Multi-function Pin Selection
  [12:8] PE5MFP — PE.5 Multi-function Pin Selection
  [4:0] PE4MFP — PE.4 Multi-function Pin Selection
0x548 SYS_GPE_MFP2 — GPIOE Multiple Function Control Register 2
  [28:24] PE11MFP — PE.11 Multi-function Pin Selection
  [20:16] PE10MFP — PE.10 Multi-function Pin Selection
  [12:8] PE9MFP — PE.9 Multi-function Pin Selection
  [4:0] PE8MFP — PE.8 Multi-function Pin Selection
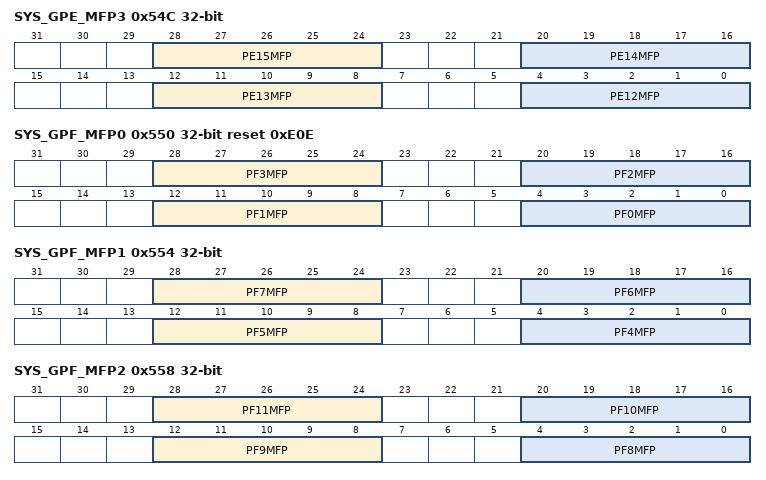
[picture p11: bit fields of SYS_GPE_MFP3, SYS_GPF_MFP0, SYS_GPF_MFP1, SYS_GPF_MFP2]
0x54C SYS_GPE_MFP3 — GPIOE Multiple Function Control Register 3
  [28:24] PE15MFP — PE.15 Multi-function Pin Selection
  [20:16] PE14MFP — PE.14 Multi-function Pin Selection
  [12:8] PE13MFP — PE.13 Multi-function Pin Selection
  [4:0] PE12MFP — PE.12 Multi-function Pin Selection
0x550 SYS_GPF_MFP0 reset 0xE0E — GPIOF Multiple Function Control Register 0
  [28:24] PF3MFP — PF.3 Multi-function Pin Selection
  [20:16] PF2MFP — PF.2 Multi-function Pin Selection
  [12:8] PF1MFP — PF.1 Multi-function Pin Selection
  [4:0] PF0MFP — PF.0 Multi-function Pin Selection
0x554 SYS_GPF_MFP1 — GPIOF Multiple Function Control Register 1
  [28:24] PF7MFP — PF.7 Multi-function Pin Selection
  [20:16] PF6MFP — PF.6 Multi-function Pin Selection
  [12:8] PF5MFP — PF.5 Multi-function Pin Selection
  [4:0] PF4MFP — PF.4 Multi-function Pin Selection
0x558 SYS_GPF_MFP2 — GPIOF Multiple Function Control Register 2
  [28:24] PF11MFP — PF.11 Multi-function Pin Selection
  [20:16] PF10MFP — PF.10 Multi-function Pin Selection
  [12:8] PF9MFP — PF.9 Multi-function Pin Selection
  [4:0] PF8MFP — PF.8 Multi-function Pin Selection
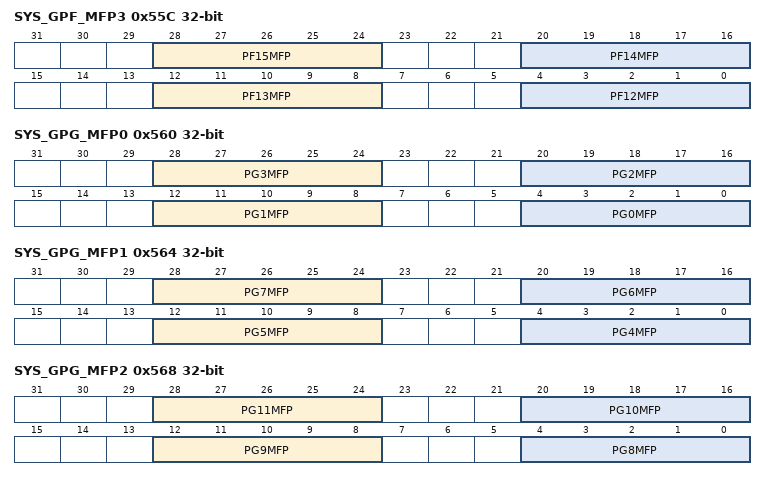
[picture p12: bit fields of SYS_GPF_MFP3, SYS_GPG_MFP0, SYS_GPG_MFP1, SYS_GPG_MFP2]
0x55C SYS_GPF_MFP3 — GPIOF Multiple Function Control Register 3
  [28:24] PF15MFP — PF.15 Multi-function Pin Selection
  [20:16] PF14MFP — PF.14 Multi-function Pin Selection
  [12:8] PF13MFP — PF.13 Multi-function Pin Selection
  [4:0] PF12MFP — PF.12 Multi-function Pin Selection
0x560 SYS_GPG_MFP0 — GPIOG Multiple Function Control Register 0
  [28:24] PG3MFP — PG.3 Multi-function Pin Selection
  [20:16] PG2MFP — PG.2 Multi-function Pin Selection
  [12:8] PG1MFP — PG.1 Multi-function Pin Selection
  [4:0] PG0MFP — PG.0 Multi-function Pin Selection
0x564 SYS_GPG_MFP1 — GPIOG Multiple Function Control Register 1
  [28:24] PG7MFP — PG.7 Multi-function Pin Selection
  [20:16] PG6MFP — PG.6 Multi-function Pin Selection
  [12:8] PG5MFP — PG.5 Multi-function Pin Selection
  [4:0] PG4MFP — PG.4 Multi-function Pin Selection
0x568 SYS_GPG_MFP2 — GPIOG Multiple Function Control Register 2
  [28:24] PG11MFP — PG.11 Multi-function Pin Selection
  [20:16] PG10MFP — PG.10 Multi-function Pin Selection
  [12:8] PG9MFP — PG.9 Multi-function Pin Selection
  [4:0] PG8MFP — PG.8 Multi-function Pin Selection
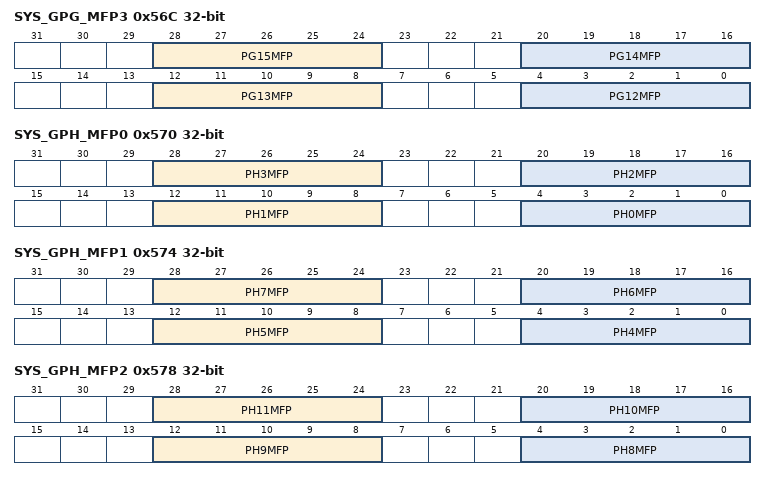
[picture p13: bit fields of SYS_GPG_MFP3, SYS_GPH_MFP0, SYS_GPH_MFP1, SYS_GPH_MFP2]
0x56C SYS_GPG_MFP3 — GPIOG Multiple Function Control Register 3
  [28:24] PG15MFP — PG.15 Multi-function Pin Selection
  [20:16] PG14MFP — PG.14 Multi-function Pin Selection
  [12:8] PG13MFP — PG.13 Multi-function Pin Selection
  [4:0] PG12MFP — PG.12 Multi-function Pin Selection
0x570 SYS_GPH_MFP0 — GPIOH Multiple Function Control Register 0
  [28:24] PH3MFP — PH.3 Multi-function Pin Selection
  [20:16] PH2MFP — PH.2 Multi-function Pin Selection
  [12:8] PH1MFP — PH.1 Multi-function Pin Selection
  [4:0] PH0MFP — PH.0 Multi-function Pin Selection
0x574 SYS_GPH_MFP1 — GPIOH Multiple Function Control Register 1
  [28:24] PH7MFP — PH.7 Multi-function Pin Selection
  [20:16] PH6MFP — PH.6 Multi-function Pin Selection
  [12:8] PH5MFP — PH.5 Multi-function Pin Selection
  [4:0] PH4MFP — PH.4 Multi-function Pin Selection
0x578 SYS_GPH_MFP2 — GPIOH Multiple Function Control Register 2
  [28:24] PH11MFP — PH.11 Multi-function Pin Selection
  [20:16] PH10MFP — PH.10 Multi-function Pin Selection
  [12:8] PH9MFP — PH.9 Multi-function Pin Selection
  [4:0] PH8MFP — PH.8 Multi-function Pin Selection
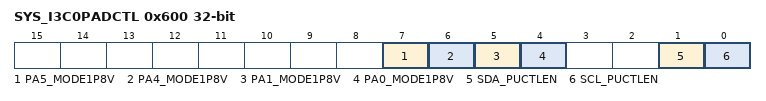
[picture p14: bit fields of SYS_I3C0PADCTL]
0x600 SYS_I3C0PADCTL — I3C0 PAD Control Register
  [7] PA5_MODE1P8V — PA.5 Additional PMOS/NMOS Enable Bit
    0=Disable(Default); 1=Enable
  [6] PA4_MODE1P8V — PA.4 Additional PMOS/NMOS Enable Bit
    0=Disable(Default); 1=Enable
  [5] PA1_MODE1P8V — PA.1 Additional PMOS/NMOS Enable Bit
    0=Disable(Default); 1=Enable
  [4] PA0_MODE1P8V — PA.0 Additional PMOS/NMOS Enable Bit
    0=Disable(Default); 1=Enable
  [1] SDA_PUCTLEN — I3C0 SDA PAD Pullup Control Enable Bit. Note 2: If set to 1, an external pullup resistor is required to provide the pullup function. Note 3: Only effective when the I3C0_SDA is selected in multi-function pin selection.
    0=I3C0 SDA PAD pullup controlled by GPIO(Default); 1=I3C0 SDA PAD pullup controlled by I3C0 controller
  [0] SCL_PUCTLEN — I3C0 SCL PAD Pullup Control Enable Bit. Note 2: If set to 1, an external pullup resistor is required to provide the pullup function. Note 3: Only effective when the I3C0_SCL is selected in multi-function pin selection.
    0=I3C0 SCL PAD pullup controlled by GPIO(Default); 1=I3C0 SCL PAD pullup controlled by I3C0 controller
